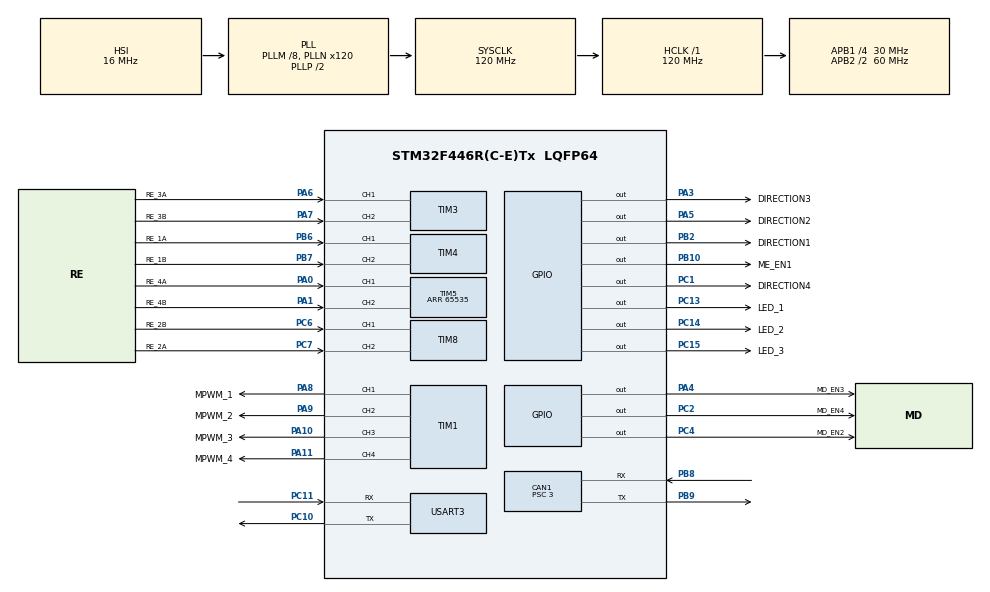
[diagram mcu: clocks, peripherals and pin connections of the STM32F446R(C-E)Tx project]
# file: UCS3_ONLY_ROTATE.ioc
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CAN1.BS1=CAN_BS1_7TQ
CAN1.BS2=CAN_BS2_2TQ
CAN1.CalculateBaudRate=1000000
CAN1.CalculateTimeBit=1000
CAN1.CalculateTimeQuantum=100.0
CAN1.Prescaler=3
Mcu.Family=STM32F4
Mcu.Name=STM32F446R(C-E)Tx
Mcu.Package=LQFP64
NVIC.PriorityGroup=NVIC_PRIORITYGROUP_4
PA0-WKUP.GPIO_Label=RE_4A
PA0-WKUP.Signal=S_TIM5_CH1
PA1.GPIO_Label=RE_4B
PA1.Signal=S_TIM5_CH2
PA10.GPIO_Label=MPWM_3
PA10.Signal=S_TIM1_CH3
PA11.GPIO_Label=MPWM_4
PA11.Signal=S_TIM1_CH4
PA3.GPIO_Label=DIRECTION3
PA3.Signal=GPIO_Output
PA4.GPIO_Label=MD_EN3
PA4.Signal=GPIO_Output
PA5.GPIO_Label=DIRECTION2
PA5.Signal=GPIO_Output
PA6.GPIO_Label=RE_3A
PA6.Signal=S_TIM3_CH1
PA7.GPIO_Label=RE_3B
PA7.Signal=S_TIM3_CH2
PA8.GPIO_Label=MPWM_1
PA8.Signal=S_TIM1_CH1
PA9.GPIO_Label=MPWM_2
PA9.Signal=S_TIM1_CH2
PB10.GPIO_Label=ME_EN1
PB10.Signal=GPIO_Output
PB2.GPIO_Label=DIRECTION1
PB2.Signal=GPIO_Output
PB6.GPIO_Label=RE_1A
PB6.Signal=S_TIM4_CH1
PB7.GPIO_Label=RE_1B
PB7.Signal=S_TIM4_CH2
PB8.Mode=CAN_Activate
PB8.Signal=CAN1_RX
PB9.Mode=CAN_Activate
PB9.Signal=CAN1_TX
PC1.GPIO_Label=DIRECTION4
PC1.Signal=GPIO_Output
PC10.Mode=Asynchronous
PC10.Signal=USART3_TX
PC11.Mode=Asynchronous
PC11.Signal=USART3_RX
PC13.GPIO_Label=LED_1
PC13.Signal=GPIO_Output
PC14-OSC32_IN.GPIO_Label=LED_2
PC14-OSC32_IN.Signal=GPIO_Output
PC15-OSC32_OUT.GPIO_Label=LED_3
PC15-OSC32_OUT.Signal=GPIO_Output
PC2.GPIO_Label=MD_EN4
PC2.Signal=GPIO_Output
PC4.GPIO_Label=MD_EN2
PC4.Signal=GPIO_Output
PC6.GPIO_Label=RE_2B
PC6.Signal=S_TIM8_CH1
PC7.GPIO_Label=RE_2A
PC7.Signal=S_TIM8_CH2
ProjectManager.HeapSize=0x200
ProjectManager.StackSize=0x400
ProjectManager.TargetToolchain=STM32CubeIDE
RCC.AHBFreq_Value=120000000
RCC.APB1CLKDivider=RCC_HCLK_DIV4
RCC.APB1Freq_Value=30000000
RCC.APB1TimFreq_Value=60000000
RCC.APB2CLKDivider=RCC_HCLK_DIV2
RCC.APB2Freq_Value=60000000
RCC.APB2TimFreq_Value=120000000
RCC.CortexFreq_Value=120000000
RCC.HCLKFreq_Value=120000000
RCC.PLLM=8
RCC.PLLN=120
RCC.SYSCLKFreq_VALUE=120000000
RCC.SYSCLKSource=RCC_SYSCLKSOURCE_PLLCLK
RCC.USBFreq_Value=120000000
RCC.VCOOutputFreq_Value=240000000
SH.S_TIM1_CH1.0=TIM1_CH1,PWM Generation1 CH1
SH.S_TIM1_CH2.0=TIM1_CH2,PWM Generation2 CH2
SH.S_TIM1_CH3.0=TIM1_CH3,PWM Generation3 CH3
SH.S_TIM1_CH4.0=TIM1_CH4,Output Compare4 CH4
SH.S_TIM3_CH1.0=TIM3_CH1,Encoder_Interface
SH.S_TIM3_CH2.0=TIM3_CH2,Encoder_Interface
SH.S_TIM4_CH1.0=TIM4_CH1,Encoder_Interface
SH.S_TIM4_CH2.0=TIM4_CH2,Encoder_Interface
SH.S_TIM5_CH1.0=TIM5_CH1,Encoder_Interface
SH.S_TIM5_CH2.0=TIM5_CH2,Encoder_Interface
SH.S_TIM8_CH1.0=TIM8_CH1,Encoder_Interface
SH.S_TIM8_CH2.0=TIM8_CH2,Encoder_Interface
TIM1.Channel-Output\ Compare4\ CH4=TIM_CHANNEL_4
TIM1.Channel-PWM\ Generation1\ CH1=TIM_CHANNEL_1
TIM1.Channel-PWM\ Generation2\ CH2=TIM_CHANNEL_2
TIM1.Channel-PWM\ Generation3\ CH3=TIM_CHANNEL_3
TIM4.EncoderMode=TIM_ENCODERMODE_TI12
TIM5.EncoderMode=TIM_ENCODERMODE_TI12
TIM5.Period=65535
TIM8.EncoderMode=TIM_ENCODERMODE_TI12
USART3.VirtualMode=VM_ASYNC
VP_TIM1_VS_ClockSourceINT.Mode=Internal
board=custom

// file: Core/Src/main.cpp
/* USER CODE BEGIN Header */
/**
  ******************************************************************************
  * @file           : main.c
  * @brief          : Main program body
  ******************************************************************************
  * @attention
  *
  * Copyright (c) 2023 STMicroelectronics.
  * All rights reserved.
  *
  * This software is licensed under terms that can be found in the LICENSE file
  * in the root directory of this software component.
  * If no LICENSE file comes with this software, it is provided AS-IS.
  *
  ******************************************************************************
  */
/* USER CODE END Header */
#include "main.h"

CAN_HandleTypeDef hcan1;

TIM_HandleTypeDef htim1;
TIM_HandleTypeDef htim3;
TIM_HandleTypeDef htim4;
TIM_HandleTypeDef htim5;
TIM_HandleTypeDef htim8;

UART_HandleTypeDef huart3;

void SystemClock_Config(void);
static void MX_GPIO_Init(void);
static void MX_CAN1_Init(void);
static void MX_TIM1_Init(void);
static void MX_TIM3_Init(void);
static void MX_TIM4_Init(void);
static void MX_TIM5_Init(void);
static void MX_TIM8_Init(void);
static void MX_USART3_UART_Init(void);

int main(void)
{

  /* MCU Configuration--------------------------------------------------------*/

  /* Reset of all peripherals, Initializes the Flash interface and the Systick. */
  HAL_Init();

  /* Configure the system clock */
  SystemClock_Config();

  /* Initialize all configured peripherals */
  MX_GPIO_Init();
  MX_CAN1_Init();
  MX_TIM1_Init();
  MX_TIM3_Init();
  MX_TIM4_Init();
  MX_TIM5_Init();
  MX_TIM8_Init();
  MX_USART3_UART_Init();
  /* USER CODE BEGIN 2 */
  float motor_pwm = 3000.0f;

  HAL_GPIO_WritePin(DIRECTION1_GPIO_Port, DIRECTION1_Pin, GPIO_PIN_SET);
  HAL_GPIO_WritePin(DIRECTION2_GPIO_Port, DIRECTION2_Pin, GPIO_PIN_SET);
  HAL_GPIO_WritePin(DIRECTION3_GPIO_Port, DIRECTION3_Pin, GPIO_PIN_SET);
  HAL_GPIO_WritePin(DIRECTION4_GPIO_Port, DIRECTION4_Pin, GPIO_PIN_SET);
  __HAL_TIM_SET_COMPARE(&htim1, TIM_CHANNEL_1, motor_pwm);
  __HAL_TIM_SET_COMPARE(&htim1, TIM_CHANNEL_2, motor_pwm);
  __HAL_TIM_SET_COMPARE(&htim1, TIM_CHANNEL_3, motor_pwm);
  __HAL_TIM_SET_COMPARE(&htim1, TIM_CHANNEL_4, motor_pwm);
  /* USER CODE END 2 */

  /* Infinite loop */
  while (1)
  {

  }
}

void SystemClock_Config(void)
{
  RCC_OscInitTypeDef RCC_OscInitStruct = {0};
  RCC_ClkInitTypeDef RCC_ClkInitStruct = {0};

  /** Configure the main internal regulator output voltage
  */
  __HAL_RCC_PWR_CLK_ENABLE();
  __HAL_PWR_VOLTAGESCALING_CONFIG(PWR_REGULATOR_VOLTAGE_SCALE3);

  /** Initializes the RCC Oscillators according to the specified parameters
  * in the RCC_OscInitTypeDef structure.
  */
  RCC_OscInitStruct.OscillatorType = RCC_OSCILLATORTYPE_HSI;
  RCC_OscInitStruct.HSIState = RCC_HSI_ON;
  RCC_OscInitStruct.HSICalibrationValue = RCC_HSICALIBRATION_DEFAULT;
  RCC_OscInitStruct.PLL.PLLState = RCC_PLL_ON;
  RCC_OscInitStruct.PLL.PLLSource = RCC_PLLSOURCE_HSI;
  RCC_OscInitStruct.PLL.PLLM = 8;
  RCC_OscInitStruct.PLL.PLLN = 120;
  RCC_OscInitStruct.PLL.PLLP = RCC_PLLP_DIV2;
  RCC_OscInitStruct.PLL.PLLQ = 2;
  RCC_OscInitStruct.PLL.PLLR = 2;
  if (HAL_RCC_OscConfig(&RCC_OscInitStruct) != HAL_OK)
  {
    Error_Handler();
  }

  /** Initializes the CPU, AHB and APB buses clocks
  */
  RCC_ClkInitStruct.ClockType = RCC_CLOCKTYPE_HCLK|RCC_CLOCKTYPE_SYSCLK
                              |RCC_CLOCKTYPE_PCLK1|RCC_CLOCKTYPE_PCLK2;
  RCC_ClkInitStruct.SYSCLKSource = RCC_SYSCLKSOURCE_PLLCLK;
  RCC_ClkInitStruct.AHBCLKDivider = RCC_SYSCLK_DIV1;
  RCC_ClkInitStruct.APB1CLKDivider = RCC_HCLK_DIV4;
  RCC_ClkInitStruct.APB2CLKDivider = RCC_HCLK_DIV2;

  if (HAL_RCC_ClockConfig(&RCC_ClkInitStruct, FLASH_LATENCY_3) != HAL_OK)
  {
    Error_Handler();
  }
}

static void MX_CAN1_Init(void)
{

  hcan1.Instance = CAN1;
  hcan1.Init.Prescaler = 3;
  hcan1.Init.Mode = CAN_MODE_NORMAL;
  hcan1.Init.SyncJumpWidth = CAN_SJW_1TQ;
  hcan1.Init.TimeSeg1 = CAN_BS1_7TQ;
  hcan1.Init.TimeSeg2 = CAN_BS2_2TQ;
  hcan1.Init.TimeTriggeredMode = DISABLE;
  hcan1.Init.AutoBusOff = DISABLE;
  hcan1.Init.AutoWakeUp = DISABLE;
  hcan1.Init.AutoRetransmission = DISABLE;
  hcan1.Init.ReceiveFifoLocked = DISABLE;
  hcan1.Init.TransmitFifoPriority = DISABLE;
  if (HAL_CAN_Init(&hcan1) != HAL_OK)
  {
    Error_Handler();
  }

}

static void MX_TIM1_Init(void)
{

  TIM_ClockConfigTypeDef sClockSourceConfig = {0};
  TIM_MasterConfigTypeDef sMasterConfig = {0};
  TIM_OC_InitTypeDef sConfigOC = {0};
  TIM_BreakDeadTimeConfigTypeDef sBreakDeadTimeConfig = {0};

  htim1.Instance = TIM1;
  htim1.Init.Prescaler = 0;
  htim1.Init.CounterMode = TIM_COUNTERMODE_UP;
  htim1.Init.Period = 65535;
  htim1.Init.ClockDivision = TIM_CLOCKDIVISION_DIV1;
  htim1.Init.RepetitionCounter = 0;
  htim1.Init.AutoReloadPreload = TIM_AUTORELOAD_PRELOAD_DISABLE;
  if (HAL_TIM_Base_Init(&htim1) != HAL_OK)
  {
    Error_Handler();
  }
  sClockSourceConfig.ClockSource = TIM_CLOCKSOURCE_INTERNAL;
  if (HAL_TIM_ConfigClockSource(&htim1, &sClockSourceConfig) != HAL_OK)
  {
    Error_Handler();
  }
  if (HAL_TIM_PWM_Init(&htim1) != HAL_OK)
  {
    Error_Handler();
  }
  if (HAL_TIM_OC_Init(&htim1) != HAL_OK)
  {
    Error_Handler();
  }
  sMasterConfig.MasterOutputTrigger = TIM_TRGO_RESET;
  sMasterConfig.MasterSlaveMode = TIM_MASTERSLAVEMODE_DISABLE;
  if (HAL_TIMEx_MasterConfigSynchronization(&htim1, &sMasterConfig) != HAL_OK)
  {
    Error_Handler();
  }
  sConfigOC.OCMode = TIM_OCMODE_PWM1;
  sConfigOC.Pulse = 0;
  sConfigOC.OCPolarity = TIM_OCPOLARITY_HIGH;
  sConfigOC.OCNPolarity = TIM_OCNPOLARITY_HIGH;
  sConfigOC.OCFastMode = TIM_OCFAST_DISABLE;
  sConfigOC.OCIdleState = TIM_OCIDLESTATE_RESET;
  sConfigOC.OCNIdleState = TIM_OCNIDLESTATE_RESET;
  if (HAL_TIM_PWM_ConfigChannel(&htim1, &sConfigOC, TIM_CHANNEL_1) != HAL_OK)
  {
    Error_Handler();
  }
  if (HAL_TIM_PWM_ConfigChannel(&htim1, &sConfigOC, TIM_CHANNEL_2) != HAL_OK)
  {
    Error_Handler();
  }
  if (HAL_TIM_PWM_ConfigChannel(&htim1, &sConfigOC, TIM_CHANNEL_3) != HAL_OK)
  {
    Error_Handler();
  }
  sConfigOC.OCMode = TIM_OCMODE_TIMING;
  if (HAL_TIM_OC_ConfigChannel(&htim1, &sConfigOC, TIM_CHANNEL_4) != HAL_OK)
  {
    Error_Handler();
  }
  sBreakDeadTimeConfig.OffStateRunMode = TIM_OSSR_DISABLE;
  sBreakDeadTimeConfig.OffStateIDLEMode = TIM_OSSI_DISABLE;
  sBreakDeadTimeConfig.LockLevel = TIM_LOCKLEVEL_OFF;
  sBreakDeadTimeConfig.DeadTime = 0;
  sBreakDeadTimeConfig.BreakState = TIM_BREAK_DISABLE;
  sBreakDeadTimeConfig.BreakPolarity = TIM_BREAKPOLARITY_HIGH;
  sBreakDeadTimeConfig.AutomaticOutput = TIM_AUTOMATICOUTPUT_DISABLE;
  if (HAL_TIMEx_ConfigBreakDeadTime(&htim1, &sBreakDeadTimeConfig) != HAL_OK)
  {
    Error_Handler();
  }
  HAL_TIM_MspPostInit(&htim1);

}

static void MX_TIM3_Init(void)
{

  TIM_Encoder_InitTypeDef sConfig = {0};
  TIM_MasterConfigTypeDef sMasterConfig = {0};

  htim3.Instance = TIM3;
  htim3.Init.Prescaler = 0;
  htim3.Init.CounterMode = TIM_COUNTERMODE_UP;
  htim3.Init.Period = 65535;
  htim3.Init.ClockDivision = TIM_CLOCKDIVISION_DIV1;
  htim3.Init.AutoReloadPreload = TIM_AUTORELOAD_PRELOAD_DISABLE;
  sConfig.EncoderMode = TIM_ENCODERMODE_TI1;
  sConfig.IC1Polarity = TIM_ICPOLARITY_RISING;
  sConfig.IC1Selection = TIM_ICSELECTION_DIRECTTI;
  sConfig.IC1Prescaler = TIM_ICPSC_DIV1;
  sConfig.IC1Filter = 0;
  sConfig.IC2Polarity = TIM_ICPOLARITY_RISING;
  sConfig.IC2Selection = TIM_ICSELECTION_DIRECTTI;
  sConfig.IC2Prescaler = TIM_ICPSC_DIV1;
  sConfig.IC2Filter = 0;
  if (HAL_TIM_Encoder_Init(&htim3, &sConfig) != HAL_OK)
  {
    Error_Handler();
  }
  sMasterConfig.MasterOutputTrigger = TIM_TRGO_RESET;
  sMasterConfig.MasterSlaveMode = TIM_MASTERSLAVEMODE_DISABLE;
  if (HAL_TIMEx_MasterConfigSynchronization(&htim3, &sMasterConfig) != HAL_OK)
  {
    Error_Handler();
  }

}

static void MX_TIM4_Init(void)
{

  TIM_Encoder_InitTypeDef sConfig = {0};
  TIM_MasterConfigTypeDef sMasterConfig = {0};

  htim4.Instance = TIM4;
  htim4.Init.Prescaler = 0;
  htim4.Init.CounterMode = TIM_COUNTERMODE_UP;
  htim4.Init.Period = 65535;
  htim4.Init.ClockDivision = TIM_CLOCKDIVISION_DIV1;
  htim4.Init.AutoReloadPreload = TIM_AUTORELOAD_PRELOAD_DISABLE;
  sConfig.EncoderMode = TIM_ENCODERMODE_TI12;
  sConfig.IC1Polarity = TIM_ICPOLARITY_RISING;
  sConfig.IC1Selection = TIM_ICSELECTION_DIRECTTI;
  sConfig.IC1Prescaler = TIM_ICPSC_DIV1;
  sConfig.IC1Filter = 0;
  sConfig.IC2Polarity = TIM_ICPOLARITY_RISING;
  sConfig.IC2Selection = TIM_ICSELECTION_DIRECTTI;
  sConfig.IC2Prescaler = TIM_ICPSC_DIV1;
  sConfig.IC2Filter = 0;
  if (HAL_TIM_Encoder_Init(&htim4, &sConfig) != HAL_OK)
  {
    Error_Handler();
  }
  sMasterConfig.MasterOutputTrigger = TIM_TRGO_RESET;
  sMasterConfig.MasterSlaveMode = TIM_MASTERSLAVEMODE_DISABLE;
  if (HAL_TIMEx_MasterConfigSynchronization(&htim4, &sMasterConfig) != HAL_OK)
  {
    Error_Handler();
  }

}

static void MX_TIM5_Init(void)
{

  TIM_Encoder_InitTypeDef sConfig = {0};
  TIM_MasterConfigTypeDef sMasterConfig = {0};

  htim5.Instance = TIM5;
  htim5.Init.Prescaler = 0;
  htim5.Init.CounterMode = TIM_COUNTERMODE_UP;
  htim5.Init.Period = 65535;
  htim5.Init.ClockDivision = TIM_CLOCKDIVISION_DIV1;
  htim5.Init.AutoReloadPreload = TIM_AUTORELOAD_PRELOAD_DISABLE;
  sConfig.EncoderMode = TIM_ENCODERMODE_TI12;
  sConfig.IC1Polarity = TIM_ICPOLARITY_RISING;
  sConfig.IC1Selection = TIM_ICSELECTION_DIRECTTI;
  sConfig.IC1Prescaler = TIM_ICPSC_DIV1;
  sConfig.IC1Filter = 0;
  sConfig.IC2Polarity = TIM_ICPOLARITY_RISING;
  sConfig.IC2Selection = TIM_ICSELECTION_DIRECTTI;
  sConfig.IC2Prescaler = TIM_ICPSC_DIV1;
  sConfig.IC2Filter = 0;
  if (HAL_TIM_Encoder_Init(&htim5, &sConfig) != HAL_OK)
  {
    Error_Handler();
  }
  sMasterConfig.MasterOutputTrigger = TIM_TRGO_RESET;
  sMasterConfig.MasterSlaveMode = TIM_MASTERSLAVEMODE_DISABLE;
  if (HAL_TIMEx_MasterConfigSynchronization(&htim5, &sMasterConfig) != HAL_OK)
  {
    Error_Handler();
  }

}

static void MX_TIM8_Init(void)
{

  TIM_Encoder_InitTypeDef sConfig = {0};
  TIM_MasterConfigTypeDef sMasterConfig = {0};

  htim8.Instance = TIM8;
  htim8.Init.Prescaler = 0;
  htim8.Init.CounterMode = TIM_COUNTERMODE_UP;
  htim8.Init.Period = 65535;
  htim8.Init.ClockDivision = TIM_CLOCKDIVISION_DIV1;
  htim8.Init.RepetitionCounter = 0;
  htim8.Init.AutoReloadPreload = TIM_AUTORELOAD_PRELOAD_DISABLE;
  sConfig.EncoderMode = TIM_ENCODERMODE_TI12;
  sConfig.IC1Polarity = TIM_ICPOLARITY_RISING;
  sConfig.IC1Selection = TIM_ICSELECTION_DIRECTTI;
  sConfig.IC1Prescaler = TIM_ICPSC_DIV1;
  sConfig.IC1Filter = 0;
  sConfig.IC2Polarity = TIM_ICPOLARITY_RISING;
  sConfig.IC2Selection = TIM_ICSELECTION_DIRECTTI;
  sConfig.IC2Prescaler = TIM_ICPSC_DIV1;
  sConfig.IC2Filter = 0;
  if (HAL_TIM_Encoder_Init(&htim8, &sConfig) != HAL_OK)
  {
    Error_Handler();
  }
  sMasterConfig.MasterOutputTrigger = TIM_TRGO_RESET;
  sMasterConfig.MasterSlaveMode = TIM_MASTERSLAVEMODE_DISABLE;
  if (HAL_TIMEx_MasterConfigSynchronization(&htim8, &sMasterConfig) != HAL_OK)
  {
    Error_Handler();
  }

}

static void MX_USART3_UART_Init(void)
{

  huart3.Instance = USART3;
  huart3.Init.BaudRate = 115200;
  huart3.Init.WordLength = UART_WORDLENGTH_8B;
  huart3.Init.StopBits = UART_STOPBITS_1;
  huart3.Init.Parity = UART_PARITY_NONE;
  huart3.Init.Mode = UART_MODE_TX_RX;
  huart3.Init.HwFlowCtl = UART_HWCONTROL_NONE;
  huart3.Init.OverSampling = UART_OVERSAMPLING_16;
  if (HAL_UART_Init(&huart3) != HAL_OK)
  {
    Error_Handler();
  }

}

static void MX_GPIO_Init(void)
{
  GPIO_InitTypeDef GPIO_InitStruct = {0};

  /* GPIO Ports Clock Enable */
  __HAL_RCC_GPIOC_CLK_ENABLE();
  __HAL_RCC_GPIOA_CLK_ENABLE();
  __HAL_RCC_GPIOB_CLK_ENABLE();

  /*Configure GPIO pin Output Level */
  HAL_GPIO_WritePin(GPIOC, LED_1_Pin|LED_2_Pin|LED_3_Pin|DIRECTION4_Pin
                          |MD_EN4_Pin|MD_EN2_Pin, GPIO_PIN_RESET);

  /*Configure GPIO pin Output Level */
  HAL_GPIO_WritePin(GPIOA, DIRECTION3_Pin|MD_EN3_Pin|DIRECTION2_Pin, GPIO_PIN_RESET);

  /*Configure GPIO pin Output Level */
  HAL_GPIO_WritePin(GPIOB, DIRECTION1_Pin|ME_EN1_Pin, GPIO_PIN_RESET);

  /*Configure GPIO pins : LED_1_Pin LED_2_Pin LED_3_Pin DIRECTION4_Pin
                           MD_EN4_Pin MD_EN2_Pin */
  GPIO_InitStruct.Pin = LED_1_Pin|LED_2_Pin|LED_3_Pin|DIRECTION4_Pin
                          |MD_EN4_Pin|MD_EN2_Pin;
  GPIO_InitStruct.Mode = GPIO_MODE_OUTPUT_PP;
  GPIO_InitStruct.Pull = GPIO_NOPULL;
  GPIO_InitStruct.Speed = GPIO_SPEED_FREQ_LOW;
  HAL_GPIO_Init(GPIOC, &GPIO_InitStruct);

  /*Configure GPIO pins : DIRECTION3_Pin MD_EN3_Pin DIRECTION2_Pin */
  GPIO_InitStruct.Pin = DIRECTION3_Pin|MD_EN3_Pin|DIRECTION2_Pin;
  GPIO_InitStruct.Mode = GPIO_MODE_OUTPUT_PP;
  GPIO_InitStruct.Pull = GPIO_NOPULL;
  GPIO_InitStruct.Speed = GPIO_SPEED_FREQ_LOW;
  HAL_GPIO_Init(GPIOA, &GPIO_InitStruct);

  /*Configure GPIO pins : DIRECTION1_Pin ME_EN1_Pin */
  GPIO_InitStruct.Pin = DIRECTION1_Pin|ME_EN1_Pin;
  GPIO_InitStruct.Mode = GPIO_MODE_OUTPUT_PP;
  GPIO_InitStruct.Pull = GPIO_NOPULL;
  GPIO_InitStruct.Speed = GPIO_SPEED_FREQ_LOW;
  HAL_GPIO_Init(GPIOB, &GPIO_InitStruct);

}

void Error_Handler(void)
{
  __disable_irq();
  while (1)
  {
  }
}
